# ESP32-S31 register map
Vendor: ESPRESSIF SYSTEMS (SHANGHAI) CO., LTD.; Series: ESP32 S-Series; File version: 1
CPU: RV32IMAFC r0p0, little endian, no MPU, FPU, 0 interrupt priority bits
Address unit: 32 bits
Registers are 32-bit, read-write, reset 0x0 unless marked. A register's access mark holds for its fields unless they carry their own. Offsets are from the block's base; [hi:lo] are bit positions; lines under a group give offsets from that group; {n}, {i} and the like mark numbered series.

## SYSTIMER — System Timer
Base 0x20399000
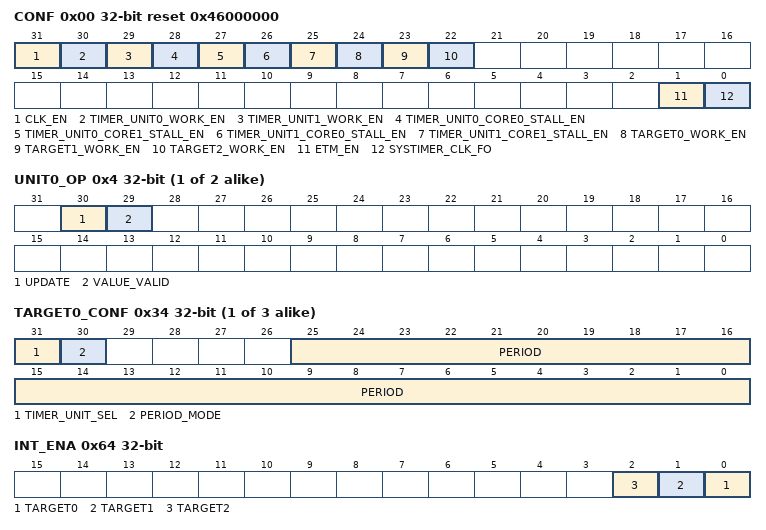
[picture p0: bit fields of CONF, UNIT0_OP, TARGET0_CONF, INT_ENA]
0x00 CONF reset 0x46000000 — Configure system timer clock
  [31] CLK_EN — Configures register clock gating. \\ 0: Only enable needed clock for register read or write operations. \\ 1: Register clock is always enabled for read and write operations. \\
  [30] TIMER_UNIT0_WORK_EN — Configures whether or not to enable UNIT0. \\ 0: Disable\\ 1: Enable\\
  [29] TIMER_UNIT1_WORK_EN — Configures whether or not to enable UNIT1. \\ 0: Disable\\ 1: Enable\\
  [28] TIMER_UNIT0_CORE0_STALL_EN — Configures whether or not UNIT0 is stalled when CORE0 is stalled. See details in SYSTIMER_TIMER_UNIT1_CORE1_STALL_EN.
  [27] TIMER_UNIT0_CORE1_STALL_EN — Configures whether or not UNIT0 is stalled when CORE1 is stalled. See details in SYSTIMER_TIMER_UNIT1_CORE1_STALL_EN.
  [26] TIMER_UNIT1_CORE0_STALL_EN — Configures whether or not UNIT1 is stalled when CORE0 is stalled. See details in SYSTIMER_TIMER_UNIT1_CORE1_STALL_EN.
  [25] TIMER_UNIT1_CORE1_STALL_EN — Configures whether or not UNIT1 is stalled when CORE1 is stalled. \\ 0: UNIT1 is not stalled. \\ 1: UNIT1 is stalled.\\
  [24] TARGET0_WORK_EN — Configures whether or not to enable COMP0. See details in SYSTIMER_TARGET2_WORK_EN.
  [23] TARGET1_WORK_EN — Configures whether or not to enable COMP1. See details in SYSTIMER_TARGET2_WORK_EN.
  [22] TARGET2_WORK_EN — Configures whether or not to enable COMP2.\\ 0: Disable\\ 1: Enable\\
  [1] ETM_EN — Configures whether or not to enable generation of ETM events.\\ 0: Disable\\ 1: Enable\\
  [0] SYSTIMER_CLK_FO — systimer clock force on
{0x4+4i} UNIT{i}_OP (i=0..1) access per field — Read UNIT{i} value to registers
  [30] UPDATE wo — Configures whether or not to update timer UNIT0, i.e., reads the UNIT0 count value to SYSTIMER_TIMER_UNIT0_VALUE_HI and SYSTIMER_TIMER_UNIT0_VALUE_LO. \\ 0: No effect\\ 1: Update timer UNIT0 \\
  [29] VALUE_VALID ro — Represents UNIT0 value is synchronized and valid.
{0xC+8i} UNIT{i}LOAD (i=0..1) group — Cluster UNIT{i}LOAD, containing UNIT?_LOAD_HI, UNIT?_LOAD_LO
  0x00 HI — High 20 bits to be loaded to UNIT0
    [19:0] LOAD_HI — Configures the value to be loaded to UNIT0, high 20 bits.
  0x04 LO — Low 32 bits to be loaded to UNIT0
    [31:0] LOAD_LO — Configures the value to be loaded to UNIT0, low 32 bits.
{0x1C+8i} TRGT{i} (i=0..2) group — Cluster TRGT{i}, containing TARGET?_HI, TARGET?_LO
  0x00 HI — Alarm value to be loaded to COMP0, high 20 bits
    [19:0] HI — Configures the alarm value to be loaded to COMP0, high 20 bits.
  0x04 LO — Alarm value to be loaded to COMP0, low 32 bits
    [31:0] LO — Configures the alarm value to be loaded to COMP0, low 32 bits.
{0x34+4i} TARGET{i}_CONF (i=0..2) — Configure COMP{i} alarm mode
  [31] TIMER_UNIT_SEL — Chooses the counter value for comparison with COMP0.\\ 0: Use the count value from UNIT$0\\ 1: Use the count value from UNIT$1\\
  [30] PERIOD_MODE — Selects the two alarm modes for COMP0. \\ 0: Target mode\\ 1: Period mode\\
  [25:0] PERIOD — Configures COMP0 alarm period.
{0x40+8i} UNIT{i}_VALUE (i=0..1) group — Cluster UNIT{i}_VALUE, containing UNIT?_VALUE_HI, UNIT?_VALUE_LO
  0x00 HI ro — UNIT0 value, high 20 bits
    [19:0] VALUE_HI — Represents UNIT0 read value, high 20 bits.
  0x04 LO ro — UNIT0 value, low 32 bits
    [31:0] VALUE_LO — Represents UNIT0 read value, low 32 bits.
{0x50+4i} COMP{i}_LOAD (i=0..2) wo — COMP{i} synchronization register
  [0] LOAD — Configures whether or not to enable COMP0 synchronization, i.e., reload the alarm value/period to COMP0.\\ 0: No effect \\ 1: Enable COMP0 synchronization\\
{0x5C+4i} UNIT{i}_LOAD (i=0..1) wo — UNIT{i} synchronization register
  [0] LOAD — Configures whether or not to reload the value of UNIT0, i.e., reloads the values of SYSTIMER_TIMER_UNIT0_VALUE_HI and SYSTIMER_TIMER_UNIT0_VALUE_LO to UNIT0. \\ 0: No effect \\ 1: Reload the value of UNIT0\\
0x64 INT_ENA — Interrupt enable register of system timer
  [n] TARGET{n} (n=0..2) — Write 1 to enable SYSTIMER_TARGET{n}_INT.
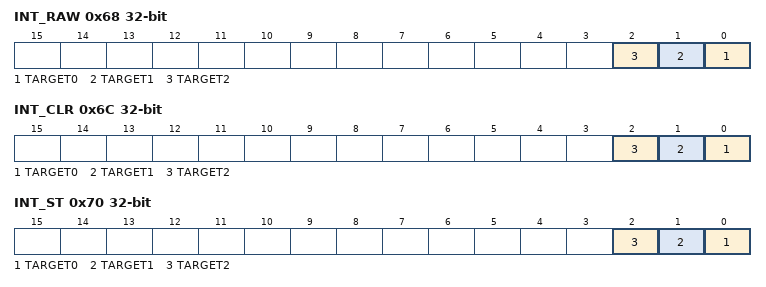
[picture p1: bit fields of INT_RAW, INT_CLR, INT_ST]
0x68 INT_RAW — Interrupt raw register of system timer
  [n] TARGET{n} (n=0..2) — The raw interrupt status of SYSTIMER_TARGET{n}_INT.
0x6C INT_CLR wo — Interrupt clear register of system timer
  [n] TARGET{n} (n=0..2) write-1-clears — Write 1 to clear SYSTIMER_TARGET{n}_INT.
0x70 INT_ST ro — Interrupt status register of system timer
  [n] TARGET{n} (n=0..2) — The interrupt status of SYSTIMER_TARGET{n}_INT.
{0x74+8i} REAL_TARGET{i} (i=0..2) group — Cluster REAL_TARGET{i}, containing REAL_TARGET?_LO, REAL_TARGET?_HI
  0x00 LO ro — Actual target value of COMP0, low 32 bits
    [31:0] LO_RO — Represents the actual target value of COMP0, low 32 bits.
  0x04 HI ro — Actual target value of COMP0, high 20 bits
    [19:0] HI_RO — Represents the actual target value of COMP0, high 20 bits.
0xFC DATE reset 0x2412270 — Version control register
  [31:0] DATE — Version control register.
